# R7FA2A1AB register map
Vendor: Renesas; Series: RA2; File version: 1.1
CPU: CM23 r1p0, little endian, MPU, no FPU, VTOR, 2 interrupt priority bits
Registers are 8-bit, read-write, reset 0x0 unless marked. A register's access mark holds for its fields unless they carry their own. Offsets are from the block's base; [hi:lo] are bit positions; {n}, {i} and the like mark numbered series; 'fields as' and 'values as' point back to an identical list.

## SRAM — SRAM Control
Base 0x40002000
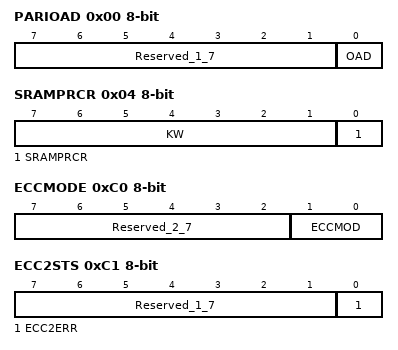
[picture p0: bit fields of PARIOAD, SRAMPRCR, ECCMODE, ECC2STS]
0x00 PARIOAD — SRAM Parity Error Operation After Detection Register
  [7:1] Reserved_1_7 — These bits are read as 0000000. The write value should be 0000000.
  [0] OAD — Operation after Detection
0x04 SRAMPRCR — SRAM Protection Register
  [7:1] KW wo — Write Key Code
  [0] SRAMPRCR — Register Write Control
0xC0 ECCMODE — ECC Operating Mode Control Register
  [7:2] Reserved_2_7 — These bits are read as 000000. The write value should be 000000.
  [1:0] ECCMOD — ECC Operating Mode Select
0xC1 ECC2STS — ECC 2-Bit Error Status Register
  [7:1] Reserved_1_7 — These bits are read as 0000000. The write value should be 0000000.
  [0] ECC2ERR write-0-clears read-modifies — ECC 2-Bit Error Status
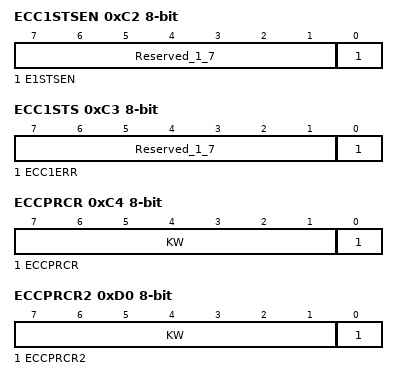
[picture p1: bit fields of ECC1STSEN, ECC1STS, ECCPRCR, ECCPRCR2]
0xC2 ECC1STSEN — ECC 1-Bit Error Information Update Enable Register
  [7:1] Reserved_1_7 — These bits are read as 0000000. The write value should be 0000000.
  [0] E1STSEN — ECC 1-Bit Error Information Update Enable
0xC3 ECC1STS — ECC 1-Bit Error Status Register
  [7:1] Reserved_1_7 — These bits are read as 0000000. The write value should be 0000000.
  [0] ECC1ERR write-0-clears read-modifies — ECC 1-Bit Error Status
0xC4 ECCPRCR — ECC Protection Register
  [7:1] KW wo — Write Key Code
  [0] ECCPRCR — Register Write Control
0xD0 ECCPRCR2 — ECC Protection Register 2
  [7:1] KW wo — Write Key Code
  [0] ECCPRCR2 — Register Write Control
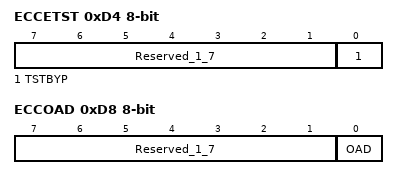
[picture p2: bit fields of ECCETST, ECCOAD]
0xD4 ECCETST — ECC Test Control Register
  [7:1] Reserved_1_7 — These bits are read as 0000000. The write value should be 0000000.
  [0] TSTBYP — ECC Bypass Select
0xD8 ECCOAD — SRAM ECC Error Operation After Detection Register
  fields as PARIOAD

## BUS — BUS Control
Base 0x40003000
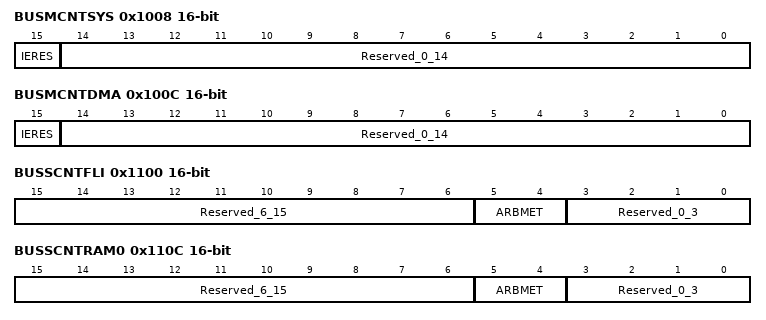
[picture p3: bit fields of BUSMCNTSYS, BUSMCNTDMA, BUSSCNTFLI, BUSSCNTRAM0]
0x1008 BUSMCNTSYS 16-bit — Master Bus Control Register SYS
  [15] IERES — Ignore Error Responses
  [14:0] Reserved_0_14 — These bits are read as 000000000000000. The write value should be 000000000000000.
0x100C BUSMCNTDMA 16-bit — Master Bus Control Register DMA
  fields as BUSMCNTSYS
0x1100 BUSSCNTFLI 16-bit — Slave Bus Control Register FLI
  [15:6] Reserved_6_15 — These bits are read as 0000000000. The write value should be 0000000000.
  [5:4] ARBMET — Arbitration MethodSpecify the priority between groups
  [3:0] Reserved_0_3 — These bits are read as 0000. The write value should be 0000.
0x110C BUSSCNTRAM0 16-bit — Slave Bus Control Register RAM0
  fields as BUSSCNTFLI
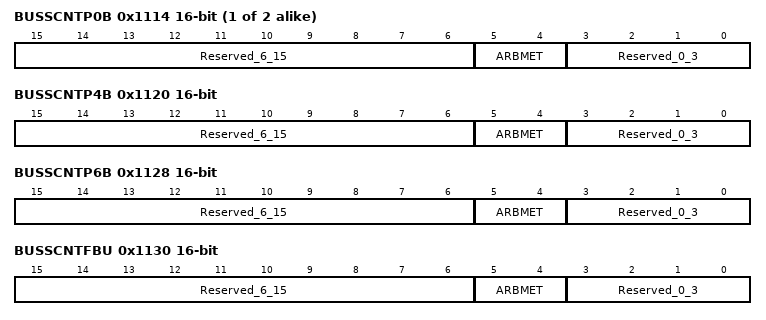
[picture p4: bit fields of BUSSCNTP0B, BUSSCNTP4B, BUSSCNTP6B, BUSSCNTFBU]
0x1114 BUSSCNT{x} (x=P0B,P2B; step 0x4) 16-bit — Slave Bus Control Register {x}
  fields as BUSSCNTFLI
0x1120 BUSSCNTP4B 16-bit — Slave Bus Control Register P4B
  fields as BUSSCNTFLI
0x1128 BUSSCNTP6B 16-bit — Slave Bus Control Register P6B
  fields as BUSSCNTFLI
0x1130 BUSSCNTFBU 16-bit — Slave Bus Control Register FBU
  fields as BUSSCNTFLI
{0x17F0+0x10*i} BUS{i}ERRADD (i=3..4) 32-bit ro reset not defined — Bus Error Address Register {i}
  [31:0] BERAD — Bus Error AddressWhen a bus error occurs, It stores an error address.
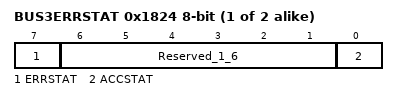
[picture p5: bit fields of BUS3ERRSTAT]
{0x17F4+0x10*i} BUS{i}ERRSTAT (i=3..4) ro (reset mask 0xFE) — Bus Error Status Register {i}
  [7] ERRSTAT — Bus Error StatusWhen bus error assert, error flag occurs.
  [6:1] Reserved_1_6 — These bits are read as 000000.
  [0] ACCSTAT — Error access statusThe status at the time of the error

## DBG — Debug Function
Base 0x4001B000
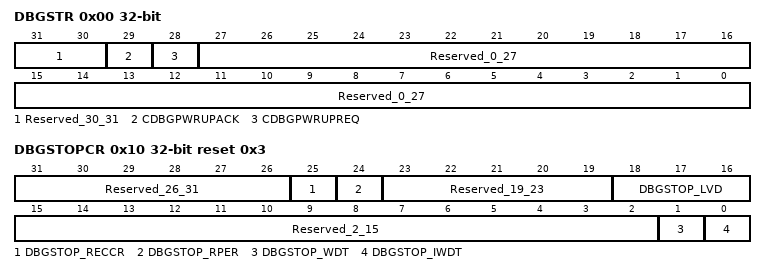
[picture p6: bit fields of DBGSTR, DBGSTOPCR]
0x00 DBGSTR 32-bit ro — Debug Status Register
  [31:30] Reserved_30_31 — These bits are read as 00.
  [29] CDBGPWRUPACK — Debug power,up acknowledge
  [28] CDBGPWRUPREQ — Debug power,up request
  [27:0] Reserved_0_27 — These bits are read as 0000000000000000000000000000.
0x10 DBGSTOPCR 32-bit reset 0x3 — Debug Stop Control Register
  [31:26] Reserved_26_31 — These bits are read as 000000. The write value should be 000000.
  [25] DBGSTOP_RECCR — Mask bit for SRAM ECC error reset/interrupt
  [24] DBGSTOP_RPER — Mask bit for RAM parity error reset/interrupt
  [23:19] Reserved_19_23 — These bits are read as 00000. The write value should be 00000.
  [18:16] DBGSTOP_LVD — b18: Mask bit for LVD2 reset/interrupt (0:enable / 1:Mask)b17: Mask bit for LVD1 reset/interrupt (0:enable / 1:Mask)b16: Mask bit for LVD0 reset (0:enable / 1:Mask)
  [15:2] Reserved_2_15 — These bits are read as 00000000000000. The write value should be 00000000000000.
  [1] DBGSTOP_WDT — Mask bit for WDT reset/interrupt
  [0] DBGSTOP_IWDT — Mask bit for IWDT reset/interrupt
